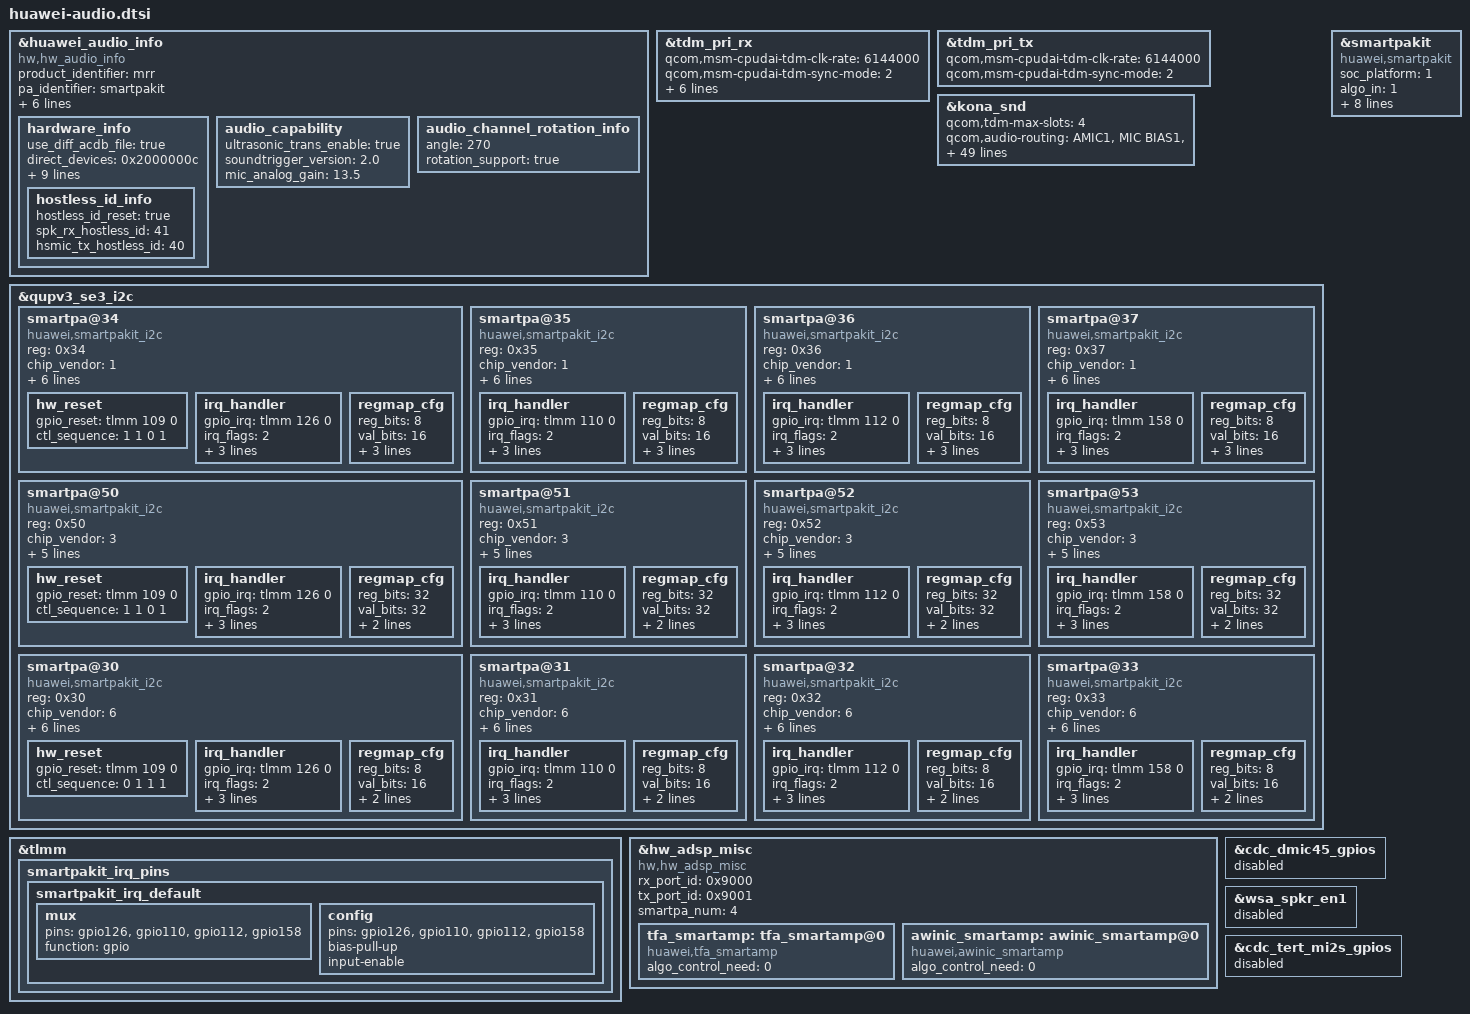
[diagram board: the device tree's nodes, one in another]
&huawei_audio_info {
	compatible = "hw,hw_audio_info";
	product_identifier = "mrr";
	pa_identifier = "smartpakit";
	smartpa_num = "4";
	voice_vol_level = "10";
	status = "ok";
	speaker_test_content = "leftspeaker,rightspeaker,subleftspeaker,subrightspeaker";
	mic_test_content = "mainmic,mainmic2,submic,submic2,submic3";
	hardware_info {
		use_diff_acdb_file = "true";
		direct_devices = "0x2000000c";
		multi_mic_enable = "true";
		backmic_record_enable = "true";
		voip_ap_algo_enable = "true";
		voip_scene_support = "true";
		get_ec_in_hal = "true";
		voip_mute_latency = "true";
		mic_num = "5";
		voip_use_multi_mic = "true";
		aec_off_use_diff_acdb_id = "true";
		status = "ok";
		hostless_id_info {
			hostless_id_reset = "true";
			spk_rx_hostless_id = "41";
			hsmic_tx_hostless_id = "40";
		};
	};

	audio_capability {
		ultrasonic_trans_enable = "true";
        soundtrigger_version = "2.0";
        mic_analog_gain = "13.5";
	};

	audio_channel_rotation_info {
		angle="270";
		rotation_support= "true";
	};
};

&tdm_pri_rx {
	qcom,msm-cpudai-tdm-clk-rate = <6144000>;
	qcom,msm-cpudai-tdm-sync-mode = <2>;

	pinctrl-names = "default", "sleep";
	pinctrl-0 = <&pri_mi2s_sck_active &pri_mi2s_ws_active
			&pri_mi2s_sd0_active &pri_mi2s_sd1_active>;
	pinctrl-1 = <&pri_mi2s_sck_sleep &pri_mi2s_ws_sleep
			&pri_mi2s_sd0_sleep &pri_mi2s_sd1_sleep>;
};

&tdm_pri_tx {
	qcom,msm-cpudai-tdm-clk-rate = <6144000>;
	qcom,msm-cpudai-tdm-sync-mode = <2>;
};

&kona_snd {
	qcom,tdm-max-slots = <4>;
	qcom,audio-routing =
		"AMIC1", "MIC BIAS1",
		"MIC BIAS1", "Analog Mic1",
		"AMIC2", "MIC BIAS2",
		"MIC BIAS2", "Analog Mic2",
		"AMIC3", "MIC BIAS1",
		"MIC BIAS1", "Analog Mic3",
		"AMIC4", "MIC BIAS3",
		"MIC BIAS3", "Analog Mic4",
		"AMIC5", "MIC BIAS3",
		"MIC BIAS3", "Analog Mic5",
		"AMIC6", "MIC BIAS3",
		"MIC BIAS3", "Analog Mic6",
		"TX DMIC0", "MIC BIAS3",
		"MIC BIAS3", "Digital Mic0",
		"TX DMIC1", "MIC BIAS3",
		"MIC BIAS3", "Digital Mic1",
		"TX DMIC2", "MIC BIAS1",
		"MIC BIAS1", "Digital Mic2",
		"TX DMIC3", "MIC BIAS1",
		"MIC BIAS1", "Digital Mic3",
		"TX DMIC5", "MIC BIAS4",
		"MIC BIAS4", "Digital Mic5",
		"IN1_HPHL", "HPHL_OUT",
		"IN2_HPHR", "HPHR_OUT",
		"IN3_AUX", "AUX_OUT",
		"TX SWR_ADC0", "ADC1_OUTPUT",
		"TX SWR_ADC1", "ADC2_OUTPUT",
		"TX SWR_ADC2", "ADC3_OUTPUT",
		"TX SWR_ADC3", "ADC4_OUTPUT",
		"TX SWR_DMIC0", "DMIC1_OUTPUT",
		"TX SWR_DMIC1", "DMIC2_OUTPUT",
		"TX SWR_DMIC2", "DMIC3_OUTPUT",
		"TX SWR_DMIC3", "DMIC4_OUTPUT",
		"TX SWR_DMIC4", "DMIC5_OUTPUT",
		"TX SWR_DMIC5", "DMIC6_OUTPUT",
		"TX SWR_DMIC6", "DMIC7_OUTPUT",
		"TX SWR_DMIC7", "DMIC8_OUTPUT",
		"WSA SRC0_INP", "SRC0",
		"WSA_TX DEC0_INP", "TX DEC0 MUX",
		"WSA_TX DEC1_INP", "TX DEC1 MUX",
		"RX_TX DEC0_INP", "TX DEC0 MUX",
		"RX_TX DEC1_INP", "TX DEC1 MUX",
		"RX_TX DEC2_INP", "TX DEC2 MUX",
		"RX_TX DEC3_INP", "TX DEC3 MUX",
		"SpkrRight IN", "WSA_SPK2 OUT",
		"VA_AIF1 CAP", "VA_SWR_CLK",
		"VA_AIF2 CAP", "VA_SWR_CLK",
		"VA_AIF3 CAP", "VA_SWR_CLK",
		"VA MIC BIAS3", "Digital Mic0",
		"VA MIC BIAS3", "Digital Mic1",
		"VA MIC BIAS1", "Digital Mic2",
		"VA MIC BIAS1", "Digital Mic3",
		"VA MIC BIAS4", "Digital Mic5",
		"VA DMIC0", "VA MIC BIAS3",
		"VA DMIC1", "VA MIC BIAS3",
		"VA DMIC2", "VA MIC BIAS1",
		"VA DMIC3", "VA MIC BIAS1",
		"VA DMIC5", "VA MIC BIAS4",
		"VA SWR_ADC1", "VA_SWR_CLK",
		"VA SWR_MIC0", "VA_SWR_CLK",
		"VA SWR_MIC1", "VA_SWR_CLK",
		"VA SWR_MIC2", "VA_SWR_CLK",
		"VA SWR_MIC3", "VA_SWR_CLK",
		"VA SWR_MIC4", "VA_SWR_CLK",
		"VA SWR_MIC5", "VA_SWR_CLK",
		"VA SWR_MIC6", "VA_SWR_CLK",
		"VA SWR_MIC7", "VA_SWR_CLK",
		"VA SWR_MIC0", "DMIC1_OUTPUT",
		"VA SWR_MIC1", "DMIC2_OUTPUT",
		"VA SWR_MIC2", "DMIC3_OUTPUT",
		"VA SWR_MIC3", "DMIC4_OUTPUT",
		"VA SWR_MIC4", "DMIC5_OUTPUT",
		"VA SWR_MIC5", "DMIC6_OUTPUT",
		"VA SWR_MIC6", "DMIC7_OUTPUT",
		"VA SWR_MIC7", "DMIC8_OUTPUT",
		"VA SWR_ADC1", "ADC2_OUTPUT";
		/delete-property/ qcom,tert-mi2s-gpios;
	qcom,is_factory_mode_remove = <0>;
};

&qupv3_se3_i2c {
	#address-cells = <1>;
	#size-cells = <0>;
	status = "ok";
	smartpa@34 {
		compatible = "huawei,smartpakit_i2c";
		reg = <0x34>;
		/* 0 MAXIM, 1 NXP, 2 TI, 3 OTHER, 4:huawei customize */
		chip_vendor = <1>;
		/* refer to smartpakit.out_device prop */
		chip_id = <0>;
		chip_model = "01-02";
		/* maybe trigger one irq after some chip reset, ext. tas2560
		 * debounce wait time unit: msecs */
		reset_debounce_wait_time = <200>;
		sync_irq_debounce_time;
		status = "ok";

		/* reg_ctl node: a node contains three data<addr value ctl_type>
		 * ctl_type: 0 read reg(default), 1 write reg, 2 only time delay
		 * value:
		 *     read:  reg number(num >= 1)
		 *     write: reg value
		 *     delay: time delay
		 * time delay unit: msecs */
		version_regs = <0x03 1 0>;
		dump_regs = <0 256 0>;

		hw_reset {
			gpio_reset = <&tlmm 109 0>; // GPIO_109
			/* gpio_state node: a node contains two data<state delay>
			* time delay unit: msecs */
			ctl_sequence = <1 1 0 1>;
		};
		irq_handler {
			gpio_irq = <&tlmm 126 0>; // GPIO_126
			/* 0x0 IRQF_TRIGGER_NONE, 0x1 IRQF_TRIGGER_RISING, 0x2 IRQF_TRIGGER_FALLING, 0x4 IRQF_TRIGGER_HIGH, 0x8 IRQF_TRIGGER_LOW*/
			irq_flags = <2>;
			/* whether or not need reset chip*/
			need_reset;
			rw_sequence = <
				0x10 1 0
				0x11 1 0
				0x13 1 0
				0x14 1 0
				0x40 1 0
				0x41 1 0
				0x42 1 0
			>;
		};

		regmap_cfg {
			reg_bits = <8>;
			val_bits = <16>;
			/* 0 REGCACHE_NONE, 1 REGCACHE_RBTREE, 2 REGCACHE_COMPRESSED, 3 REGCACHE_FLAT */
			cache_type = <0>;
			max_register = <0xff>;
			reg_defaults = <
				0x00 0x1801
				0x01 0x0014
			>;
		};
	};

	smartpa@35 {
		compatible = "huawei,smartpakit_i2c";
		reg = <0x35>;
		/* 0 MAXIM, 1 NXP, 2 TI, 3 OTHER, 4:huawei customize */
		chip_vendor = <1>;
		/* refer to smartpakit.out_device prop */
		chip_id = <1>;
		chip_model = "01-02";
		/* maybe trigger one irq after some chip reset, ext. tas2560
		 * debounce wait time unit: msecs */
		reset_debounce_wait_time = <200>;
		sync_irq_debounce_time;
		status = "ok";

		/* reg_ctl node: a node contains three data<addr value ctl_type>
		* ctl_type: 0 read reg(default), 1 write reg, 2 only time delay
		* value:
		*     read:  reg number(num >= 1)
		*     write: reg value
		*     delay: time delay
		* time delay unit: msecs */
		version_regs = <0x03 1 0>;
		dump_regs = <0 256 0>;

		irq_handler {
			gpio_irq = <&tlmm 110 0>; // GPIO_110
			/* 0x0 IRQF_TRIGGER_NONE, 0x1 IRQF_TRIGGER_RISING, 0x2 IRQF_TRIGGER_FALLING, 0x4 IRQF_TRIGGER_HIGH, 0x8 IRQF_TRIGGER_LOW*/
			irq_flags = <2>;
			/* whether or not need reset chip*/
			need_reset;
			rw_sequence = <
				0x10 1 0
				0x11 1 0
				0x13 1 0
				0x14 1 0
				0x40 1 0
				0x41 1 0
				0x42 1 0
			>;
		};

		regmap_cfg {
			reg_bits = <8>;
			val_bits = <16>;
			/* 0 REGCACHE_NONE, 1 REGCACHE_RBTREE, 2 REGCACHE_COMPRESSED, 3 REGCACHE_FLAT */
			cache_type = <0>;
			max_register = <0xff>;
			reg_defaults = <
				0x00 0x1801
				0x01 0x0014
			>;
		};
	};

	smartpa@36 {
		compatible = "huawei,smartpakit_i2c";
		reg = <0x36>;
		/* 0 MAXIM, 1 NXP, 2 TI, 3 OTHER, 4:huawei customize */
		chip_vendor = <1>;
		/* refer to smartpakit.out_device prop */
		chip_id = <2>;
		chip_model = "01-02";
		/* maybe trigger one irq after some chip reset, ext. tas2560
		 * debounce wait time unit: msecs */
		reset_debounce_wait_time = <200>;
		sync_irq_debounce_time;
		status = "ok";

		/* reg_ctl node: a node contains three data<addr value ctl_type>
		 * ctl_type: 0 read reg(default), 1 write reg, 2 only time delay
		 * value:
		 *     read:  reg number(num >= 1)
		 *     write: reg value
		 *     delay: time delay
		 * time delay unit: msecs */
		version_regs = <0x03 1 0>;
		dump_regs = <0 256 0>;

		irq_handler {
			gpio_irq = <&tlmm 112 0>; // GPIO_112
			/* 0x0 IRQF_TRIGGER_NONE, 0x1 IRQF_TRIGGER_RISING, 0x2 IRQF_TRIGGER_FALLING, 0x4 IRQF_TRIGGER_HIGH, 0x8 IRQF_TRIGGER_LOW*/
			irq_flags = <2>;
			/* whether or not need reset chip*/
			need_reset;
			rw_sequence = <
				0x10 1 0
				0x11 1 0
				0x13 1 0
				0x14 1 0
				0x40 1 0
				0x41 1 0
				0x42 1 0
			>;
		};
		regmap_cfg {
			reg_bits = <8>;
			val_bits = <16>;
			/* 0 REGCACHE_NONE, 1 REGCACHE_RBTREE, 2 REGCACHE_COMPRESSED, 3 REGCACHE_FLAT */
			cache_type = <0>;
			max_register = <0xff>;
			reg_defaults = <
				0x00 0x1801
				0x01 0x0014
			>;
		};
	};

	smartpa@37 {
		compatible = "huawei,smartpakit_i2c";
		reg = <0x37>;
		/* 0 MAXIM, 1 NXP, 2 TI, 3 OTHER, 4:huawei customize */
		chip_vendor = <1>;
		/* refer to smartpakit.out_device prop */
		chip_id = <3>;
		chip_model = "01-02";
		/* maybe trigger one irq after some chip reset, ext. tas2560
		 * debounce wait time unit: msecs */
		reset_debounce_wait_time = <200>;
		sync_irq_debounce_time;
		status = "ok";

		/* reg_ctl node: a node contains three data<addr value ctl_type>
		 * ctl_type: 0 read reg(default), 1 write reg, 2 only time delay
		 * value:
		 *     read:  reg number(num >= 1)
		 *     write: reg value
		 *     delay: time delay
		 * time delay unit: msecs */
		version_regs = <0x03 1 0>;
		dump_regs = <0 256 0>;

		irq_handler {
			gpio_irq = <&tlmm 158 0>; // GPIO_158
			/* 0x0 IRQF_TRIGGER_NONE, 0x1 IRQF_TRIGGER_RISING, 0x2 IRQF_TRIGGER_FALLING, 0x4 IRQF_TRIGGER_HIGH, 0x8 IRQF_TRIGGER_LOW*/
			irq_flags = <2>;
			/* whether or not need reset chip*/
			need_reset;
			rw_sequence = <
				0x10 1 0
				0x11 1 0
				0x13 1 0
				0x14 1 0
				0x40 1 0
				0x41 1 0
				0x42 1 0
			>;
		};
		regmap_cfg {
			reg_bits = <8>;
			val_bits = <16>;
			/* 0 REGCACHE_NONE, 1 REGCACHE_RBTREE, 2 REGCACHE_COMPRESSED, 3 REGCACHE_FLAT */
			cache_type = <0>;
			max_register = <0xff>;
			reg_defaults = <
				0x00 0x1801
				0x01 0x0014
			>;
		};
	};

	smartpa@50{
		compatible = "huawei,smartpakit_i2c";
		reg = <0x50>;
		/* 4:huawei customize */
		chip_vendor = <3>;
		/* refer to smartpakit.out_device prop */
		chip_id = <0>;
		chip_model = "03-01";
		status = "ok";

		/* reg_ctl node: a node contains three data<addr value ctl_type>
		 * ctl_type: 0 read reg(default), 1 write reg, 2 only time delay
		 * value:
		 *     read:  reg number(num >= 1)
		 *     write: reg value
		 *     delay: time delay
		 * time delay unit: msecs
		 */
		version_regs = <0x0 1 0>;
		dump_regs = <
			0x000000 1          0
			0x000008 1          0
			0x002014 0x21       0
			0x002400 1          0
			0x002c04 0xd        0
			0x003800 0x31       0
			0x004004 1          0
			0x004220 1          0
			0x004300 1          0
			0x004800 0x3d       0
			0x004C00 1          0
			0x004C20 0x15       0
			0x006000 1          0
			0x006404 0x11       0
			0x006450 1          0
			0x006800 0x9        0
			0x006C04 1          0
			0xd00000 0x4d       0
			0xe02800 1          0>;

		hw_reset {
			gpio_reset = <&tlmm 109 0>; // GPIO_109
			/* gpio_state node: a node contains two data<state delay>
			 * time delay unit: msecs
			 */
			ctl_sequence = <1 1 0 1>;
		};

		irq_handler {
			gpio_irq = <&tlmm 126 0>; // GPIO_126
			/* 0x0 IRQF_TRIGGER_NONE, 0x1 IRQF_TRIGGER_RISING, 0x2 IRQF_TRIGGER_FALLING, 0x4 IRQF_TRIGGER_HIGH, 0x8 IRQF_TRIGGER_LOW */
			irq_flags = <2>;
			/* whether or not need reset chip */
			need_reset;
			rw_sequence = <
				0xd00020 1          0
				0xd00024 1          0
				0xd00028 1          0
				0xd0002c 1          0
				0xd00000 0xffffffff 1
				0xd00004 0xffffffff 1
				0xd00008 0xffffffff 1
				0xd0000c 0xffffffff 1
			>;
		};

		regmap_cfg {
			reg_bits = <32>;
			val_bits = <32>;
			/* 0 REGCACHE_NONE, 1 REGCACHE_RBTREE, 2 REGCACHE_COMPRESSED, 3 REGCACHE_FLAT */
			cache_type = <0>;
			max_register = <0xe0ffff>;
		};
	};

	smartpa@51{
		compatible = "huawei,smartpakit_i2c";
		reg = <0x51>;
		/* 4:huawei customize */
		chip_vendor = <3>;
		/* refer to smartpakit.out_device prop */
		chip_id = <1>;
		chip_model = "03-01";
		status = "ok";

		/* reg_ctl node: a node contains three data<addr value ctl_type>
		 * ctl_type: 0 read reg(default), 1 write reg, 2 only time delay
		 * value:
		 *     read:  reg number(num >= 1)
		 *     write: reg value
		 *     delay: time delay
		 * time delay unit: msecs
		 */
		version_regs = <0x0 1 0>;
		dump_regs = <
			0x000000 1          0
			0x000008 1          0
			0x002014 0x21       0
			0x002400 1          0
			0x002c04 0xd        0
			0x003800 0x31       0
			0x004004 1          0
			0x004220 1          0
			0x004300 1          0
			0x004800 0x3d       0
			0x004C00 1          0
			0x004C20 0x15       0
			0x006000 1          0
			0x006404 0x11       0
			0x006450 1          0
			0x006800 0x9        0
			0x006C04 1          0
			0xd00000 0x4d       0
			0xe02800 1          0>;

		irq_handler {
			gpio_irq = <&tlmm 110 0>; // GPIO_110
			/* 0x0 IRQF_TRIGGER_NONE, 0x1 IRQF_TRIGGER_RISING, 0x2 IRQF_TRIGGER_FALLING, 0x4 IRQF_TRIGGER_HIGH, 0x8 IRQF_TRIGGER_LOW */
			irq_flags = <2>;
			/* whether or not need reset chip */
			need_reset;
			rw_sequence = <
				0xd00020 1          0
				0xd00024 1          0
				0xd00028 1          0
				0xd0002c 1          0
				0xd00000 0xffffffff 1
				0xd00004 0xffffffff 1
				0xd00008 0xffffffff 1
				0xd0000c 0xffffffff 1
			>;
		};

		regmap_cfg {
			reg_bits = <32>;
			val_bits = <32>;
			/* 0 REGCACHE_NONE, 1 REGCACHE_RBTREE, 2 REGCACHE_COMPRESSED, 3 REGCACHE_FLAT */
			cache_type = <0>;
			max_register = <0xe0ffff>;
		};
	};

	smartpa@52{
		compatible = "huawei,smartpakit_i2c";
		reg = <0x52>;
		/* 4:huawei customize */
		chip_vendor = <3>;
		/* refer to smartpakit.out_device prop */
		chip_id = <2>;
		chip_model = "03-01";
		status = "ok";

		/* reg_ctl node: a node contains three data<addr value ctl_type>
		 * ctl_type: 0 read reg(default), 1 write reg, 2 only time delay
		 * value:
		 *     read:  reg number(num >= 1)
		 *     write: reg value
		 *     delay: time delay
		 * time delay unit: msecs
		 */
		version_regs = <0x0 1 0>;
		dump_regs = <
			0x000000 1          0
			0x000008 1          0
			0x002014 0x21       0
			0x002400 1          0
			0x002c04 0xd        0
			0x003800 0x31       0
			0x004004 1          0
			0x004220 1          0
			0x004300 1          0
			0x004800 0x3d       0
			0x004C00 1          0
			0x004C20 0x15       0
			0x006000 1          0
			0x006404 0x11       0
			0x006450 1          0
			0x006800 0x9        0
			0x006C04 1          0
			0xd00000 0x4d       0
			0xe02800 1          0>;

		irq_handler {
			gpio_irq = <&tlmm 112 0>; // GPIO_112
			/* 0x0 IRQF_TRIGGER_NONE, 0x1 IRQF_TRIGGER_RISING, 0x2 IRQF_TRIGGER_FALLING, 0x4 IRQF_TRIGGER_HIGH, 0x8 IRQF_TRIGGER_LOW */
			irq_flags = <2>;
			/* whether or not need reset chip */
			need_reset;
			rw_sequence = <
				0xd00020 1          0
				0xd00024 1          0
				0xd00028 1          0
				0xd0002c 1          0
				0xd00000 0xffffffff 1
				0xd00004 0xffffffff 1
				0xd00008 0xffffffff 1
				0xd0000c 0xffffffff 1
			>;
		};

		regmap_cfg {
			reg_bits = <32>;
			val_bits = <32>;
			/* 0 REGCACHE_NONE, 1 REGCACHE_RBTREE, 2 REGCACHE_COMPRESSED, 3 REGCACHE_FLAT */
			cache_type = <0>;
			max_register = <0xe0ffff>;
		};
	};

	smartpa@53{
		compatible = "huawei,smartpakit_i2c";
		reg = <0x53>;
		/* 4:huawei customize */
		chip_vendor = <3>;
		/* refer to smartpakit.out_device prop */
		chip_id = <3>;
		chip_model = "03-01";
		status = "ok";

		/* reg_ctl node: a node contains three data<addr value ctl_type>
		 * ctl_type: 0 read reg(default), 1 write reg, 2 only time delay
		 * value:
		 *     read:  reg number(num >= 1)
		 *     write: reg value
		 *     delay: time delay
		 * time delay unit: msecs
		 */
		version_regs = <0x0 1 0>;
		dump_regs = <
			0x000000 1          0
			0x000008 1          0
			0x002014 0x21       0
			0x002400 1          0
			0x002c04 0xd        0
			0x003800 0x31       0
			0x004004 1          0
			0x004220 1          0
			0x004300 1          0
			0x004800 0x3d       0
			0x004C00 1          0
			0x004C20 0x15       0
			0x006000 1          0
			0x006404 0x11       0
			0x006450 1          0
			0x006800 0x9        0
			0x006C04 1          0
			0xd00000 0x4d       0
			0xe02800 1          0>;

		irq_handler {
			gpio_irq = <&tlmm 158 0>; // GPIO_158
			/* 0x0 IRQF_TRIGGER_NONE, 0x1 IRQF_TRIGGER_RISING, 0x2 IRQF_TRIGGER_FALLING, 0x4 IRQF_TRIGGER_HIGH, 0x8 IRQF_TRIGGER_LOW */
			irq_flags = <2>;
			/* whether or not need reset chip */
			need_reset;
			rw_sequence = <
				0xd00020 1          0
				0xd00024 1          0
				0xd00028 1          0
				0xd0002c 1          0
				0xd00000 0xffffffff 1
				0xd00004 0xffffffff 1
				0xd00008 0xffffffff 1
				0xd0000c 0xffffffff 1
			>;
		};

		regmap_cfg {
			reg_bits = <32>;
			val_bits = <32>;
			/* 0 REGCACHE_NONE, 1 REGCACHE_RBTREE, 2 REGCACHE_COMPRESSED, 3 REGCACHE_FLAT */
			cache_type = <0>;
			max_register = <0xe0ffff>;
		};
	};

	smartpa@30{
		compatible = "huawei,smartpakit_i2c";
		reg = <0x30>;
		/* 0 MAXIM, 1 NXP, 2 TI, 3 OTHER, 4:huawei customize */
		chip_vendor = <6>;
		/* refer to smartpakit.out_device prop */
		chip_id = <0>;
		chip_model = "06-01";
		/* maybe trigger one irq after some chip reset, ext. tas2560
		 * debounce wait time unit: msecs */
		reset_debounce_wait_time = <200>;
		sync_irq_debounce_time;
		status = "ok";

		/* reg_ctl node: a node contains three data<addr value ctl_type>
		 * ctl_type: 0 read reg(default), 1 write reg, 2 only time delay
		 * value:
		 *     read:  reg number(num >= 1)
		 *     write: reg value
		 *     delay: time delay
		 * time delay unit: msecs */
		version_regs = <0x00 1 0>;
		dump_regs = <0 256 0>;
		hw_reset {
			gpio_reset = <&tlmm 109 0>; // GPIO_109
			/* gpio_state node: a node contains two data<state delay>
			 * time delay unit: msecs */
			ctl_sequence = <0 1 1 1>;
		};
		irq_handler {
			gpio_irq = <&tlmm 126 0>; // GPIO_126
			/* 0x0 IRQF_TRIGGER_NONE, 0x1 IRQF_TRIGGER_RISING, 0x2 IRQF_TRIGGER_FALLING, 0x4 IRQF_TRIGGER_HIGH, 0x8 IRQF_TRIGGER_LOW*/
			irq_flags = <2>;
			/* whether or not need reset chip*/
			need_reset;
			rw_sequence = <
				0x00 8 0
				0x09 5 0
				0x12 3 0
				0x60 2 0
				0x78 1 0
				0x7a 1 0
			>;
		};
		regmap_cfg {
			reg_bits = <8>;
			val_bits = <16>;
			/* 0 REGCACHE_NONE, 1 REGCACHE_RBTREE, 2 REGCACHE_COMPRESSED, 3 REGCACHE_FLAT */
			cache_type = <0>;
			max_register = <0xff>;
		};
	};

	smartpa@31{
		compatible = "huawei,smartpakit_i2c";
		reg = <0x31>;
		/* 0 MAXIM, 1 NXP, 2 TI, 3 OTHER, 4:huawei customize */
		chip_vendor = <6>;
		/* refer to smartpakit.out_device prop */
		chip_id = <1>;
		chip_model = "06-01";
		/* maybe trigger one irq after some chip reset, ext. tas2560
		 * debounce wait time unit: msecs */
		reset_debounce_wait_time = <200>;
		sync_irq_debounce_time;
		status = "ok";

		/* reg_ctl node: a node contains three data<addr value ctl_type>
		 * ctl_type: 0 read reg(default), 1 write reg, 2 only time delay
		 * value:
		 *     read:  reg number(num >= 1)
		 *     write: reg value
		 *     delay: time delay
		 * time delay unit: msecs */
		version_regs = <0x00 1 0>;
		dump_regs = <0 256 0>;

		irq_handler {
			gpio_irq = <&tlmm 110 0>; // GPIO_110
			/* 0x0 IRQF_TRIGGER_NONE, 0x1 IRQF_TRIGGER_RISING, 0x2 IRQF_TRIGGER_FALLING, 0x4 IRQF_TRIGGER_HIGH, 0x8 IRQF_TRIGGER_LOW*/
			irq_flags = <2>;
			/* whether or not need reset chip*/
			need_reset;
			rw_sequence = <
				0x00 8 0
				0x09 5 0
				0x12 3 0
				0x60 2 0
				0x78 1 0
				0x7a 1 0
			>;
		};
		regmap_cfg {
			reg_bits = <8>;
			val_bits = <16>;
			/* 0 REGCACHE_NONE, 1 REGCACHE_RBTREE, 2 REGCACHE_COMPRESSED, 3 REGCACHE_FLAT */
			cache_type = <0>;
			max_register = <0xff>;
		};
	};

	smartpa@32{
		compatible = "huawei,smartpakit_i2c";
		reg = <0x32>;
		/* 0 MAXIM, 1 NXP, 2 TI, 3 OTHER, 4:huawei customize */
		chip_vendor = <6>;
		/* refer to smartpakit.out_device prop */
		chip_id = <2>;
		chip_model = "06-01";
		/* maybe trigger one irq after some chip reset, ext. tas2560
		 * debounce wait time unit: msecs */
		reset_debounce_wait_time = <200>;
		sync_irq_debounce_time;
		status = "ok";

		/* reg_ctl node: a node contains three data<addr value ctl_type>
		 * ctl_type: 0 read reg(default), 1 write reg, 2 only time delay
		 * value:
		 *     read:  reg number(num >= 1)
		 *     write: reg value
		 *     delay: time delay
		 * time delay unit: msecs */
		version_regs = <0x00 1 0>;
		dump_regs = <0 256 0>;

		irq_handler {
			gpio_irq = <&tlmm 112 0>; // GPIO_112
			/* 0x0 IRQF_TRIGGER_NONE, 0x1 IRQF_TRIGGER_RISING, 0x2 IRQF_TRIGGER_FALLING, 0x4 IRQF_TRIGGER_HIGH, 0x8 IRQF_TRIGGER_LOW*/
			irq_flags = <2>;
			/* whether or not need reset chip*/
			need_reset;
			rw_sequence = <
				0x00 8 0
				0x09 5 0
				0x12 3 0
				0x60 2 0
				0x78 1 0
				0x7a 1 0
			>;
		};
		regmap_cfg {
			reg_bits = <8>;
			val_bits = <16>;
			/* 0 REGCACHE_NONE, 1 REGCACHE_RBTREE, 2 REGCACHE_COMPRESSED, 3 REGCACHE_FLAT */
			cache_type = <0>;
			max_register = <0xff>;
		};
	};

	smartpa@33{
		compatible = "huawei,smartpakit_i2c";
		reg = <0x33>;
		/* 0 MAXIM, 1 NXP, 2 TI, 3 OTHER, 4:huawei customize */
		chip_vendor = <6>;
		/* refer to smartpakit.out_device prop */
		chip_id = <3>;
		chip_model = "06-01";
		/* maybe trigger one irq after some chip reset, ext. tas2560
		 * debounce wait time unit: msecs */
		reset_debounce_wait_time = <200>;
		sync_irq_debounce_time;
		status = "ok";

		/* reg_ctl node: a node contains three data<addr value ctl_type>
		 * ctl_type: 0 read reg(default), 1 write reg, 2 only time delay
		 * value:
		 *     read:  reg number(num >= 1)
		 *     write: reg value
		 *     delay: time delay
		 * time delay unit: msecs */
		version_regs = <0x00 1 0>;
		dump_regs = <0 256 0>;

		irq_handler {
			gpio_irq = <&tlmm 158 0>; // GPIO_158
			/* 0x0 IRQF_TRIGGER_NONE, 0x1 IRQF_TRIGGER_RISING, 0x2 IRQF_TRIGGER_FALLING, 0x4 IRQF_TRIGGER_HIGH, 0x8 IRQF_TRIGGER_LOW*/
			irq_flags = <2>;
			/* whether or not need reset chip*/
			need_reset;
			rw_sequence = <
				0x00 8 0
				0x09 5 0
				0x12 3 0
				0x60 2 0
				0x78 1 0
				0x7a 1 0
			>;
		};
		regmap_cfg {
			reg_bits = <8>;
			val_bits = <16>;
			/* 0 REGCACHE_NONE, 1 REGCACHE_RBTREE, 2 REGCACHE_COMPRESSED, 3 REGCACHE_FLAT */
			cache_type = <0>;
			max_register = <0xff>;
		};
	};
};


&tlmm {
	smartpakit_irq_pins: smartpakit_irq_pins {
		smartpakit_irq_default: smartpakit_irq_default {
			mux {
				pins = "gpio126", "gpio110", "gpio112", "gpio158";
				function = "gpio";
			};

			config {
				pins = "gpio126", "gpio110", "gpio112", "gpio158";
				bias-pull-up;
				input-enable;
			};
		};
	};
};


&smartpakit {
	compatible = "huawei,smartpakit";
	/* 0 hisi, 1 qcom */
	soc_platform = <1>;
	/* algo running on: 0 codec_dsp, 1 soc_dsp, 2 smartpa_dsp, 3 simple pa(not smpartpa), 4 simple pa(with i2c) */
	algo_in = <1>;
	/* algo_in params need match out_device for smartpa.
	 * Now, up to only support eight pa, so out_device = <0 0 0 0 0 0 0 0>;
	 * 1. This array is arranged in the following order:
	 *    <0 1 2 3>
	 *    <pril prir secl secr>
	 * 2. This array element value is 0 or 1:
	 *    smartpa: 0 speaker, 1 receiver
	 *    simple pa: out_device not applicable, only set 0 to indicate pa_num
	 * 3. The length of this array is variable, for example:
	 *    single pa: out_device = <0>;
	 *    two pa: out_device = <0 0>;
	 *    four pa: out_device = <1 1 0 0>;
	 *    eight pa: out_device = <0 0 0 0 0 0 0 0>; */
	out_device = <0 0 0 0>;
	/* param_version: 1 mixed smartpa param support */
	param_version = <1>;
	cali_data_update_mode = <1>;
	status = "ok";

	smartpakit_irq_pinctrl;
	pinctrl-names = "default";
	pinctrl-0 = <&smartpakit_irq_default>;
	i2c_ops_retry_adapt_enable;
	i2c_ops_retry_time = <6>;
	i2c_ops_retry_delay = <2>;
};

&hw_adsp_misc {
	compatible = "hw,hw_adsp_misc";
	rx_port_id = <0x9000>;
	tx_port_id = <0x9001>;
	smartpa_num = <4>;
	status = "ok";

	tfa_smartamp: tfa_smartamp@0{
		compatible = "huawei,tfa_smartamp";
		algo_control_need = <0>;
		status = "ok";
	};

	awinic_smartamp: awinic_smartamp@0{
		compatible = "huawei,awinic_smartamp";
		algo_control_need = <0>;
		status = "ok";
	};
};

&cdc_dmic45_gpios {
        status = "disabled";
};

&wsa_spkr_en1 {
	status = "disabled";
};

&cdc_tert_mi2s_gpios {
	status = "disabled";
};
